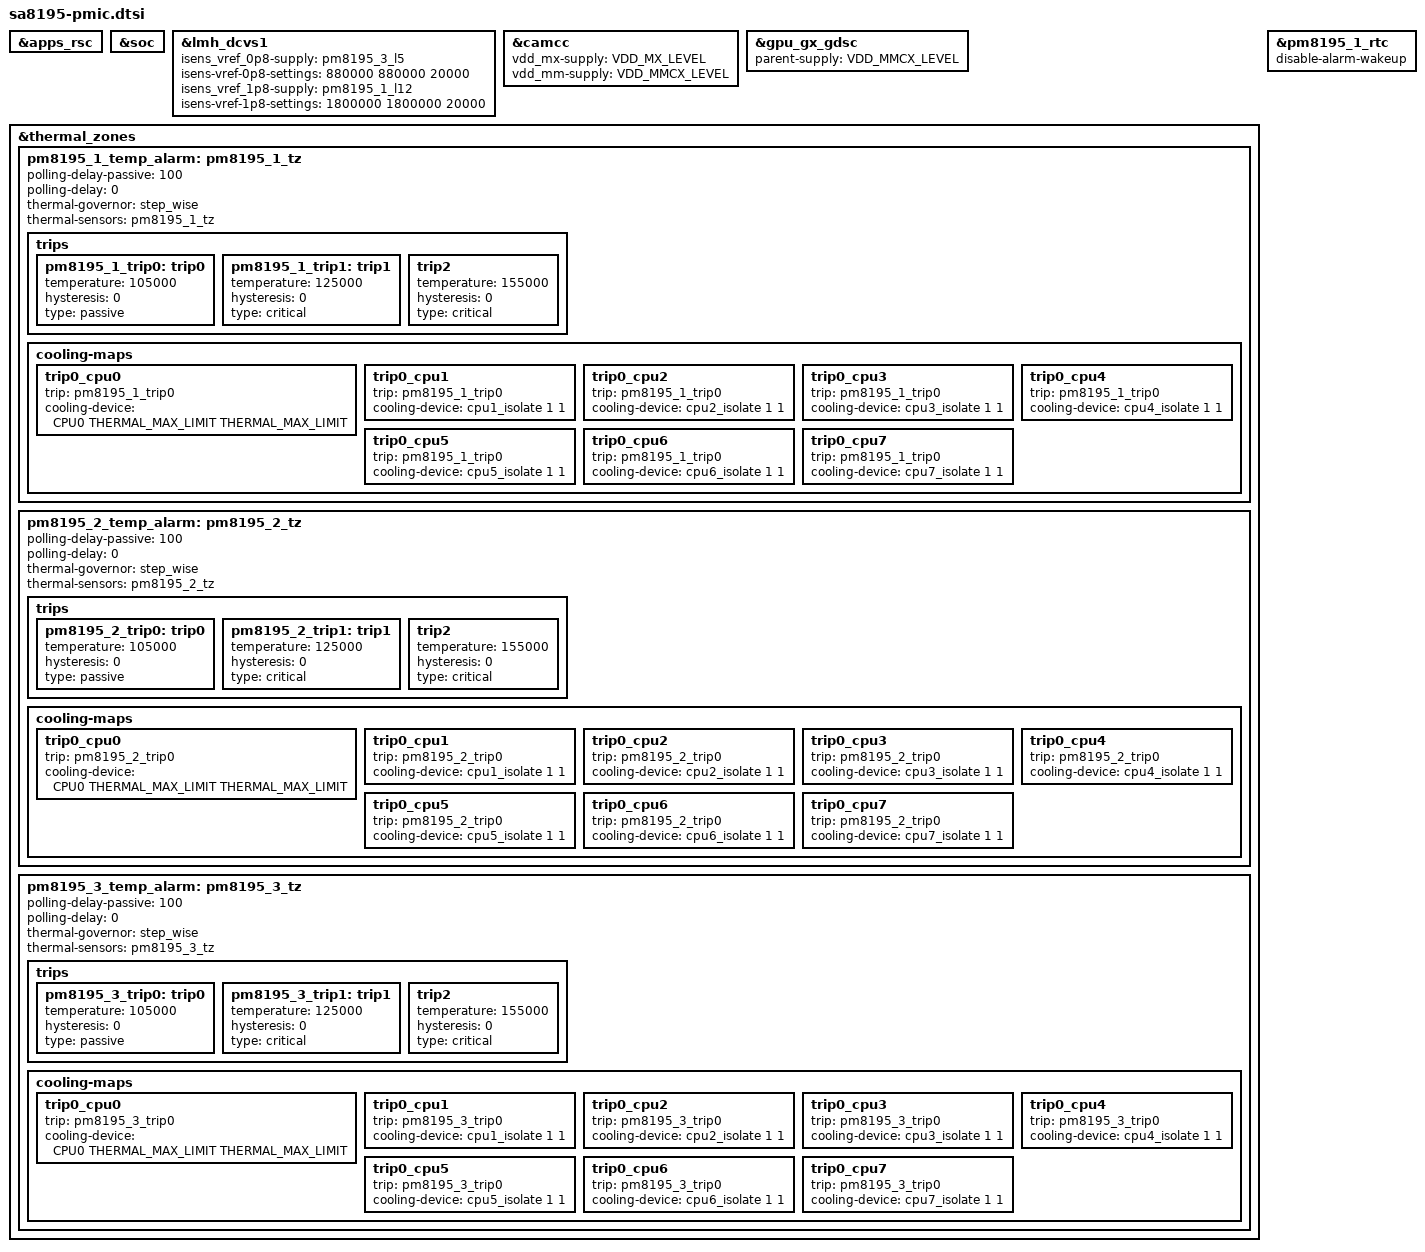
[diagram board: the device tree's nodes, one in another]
/* Remove regulator nodes specific to sdmshrike */
&apps_rsc {
	/* Logical rails */
	/delete-node/ rpmh-regulator-cxlvl;
	/delete-node/ rpmh-regulator-mxlvl;
	/delete-node/ rpmh-regulator-gfxlvl;
	/delete-node/ rpmh-regulator-lmxlvl;
	/delete-node/ rpmh-regulator-lcxlvl;
	/delete-node/ rpmh-regulator-mmcxlvl;
	/delete-node/ rpmh-regulator-msslvl;
	/delete-node/ rpmh-regulator-ebilvl;

	/* PM8150_1 regulators */
	/delete-node/ rpmh-regulator-smpa5;
	/delete-node/ rpmh-regulator-ldoa3;
	/delete-node/ rpmh-regulator-ldoa5;
	/delete-node/ rpmh-regulator-ldoa6;
	/delete-node/ rpmh-regulator-ldoa7;
	/delete-node/ rpmh-regulator-ldoa9;
	/delete-node/ rpmh-regulator-ldoa11;
	/delete-node/ rpmh-regulator-ldoa12;
	/delete-node/ rpmh-regulator-ldoa13;
	/delete-node/ rpmh-regulator-ldoa15;
	/delete-node/ rpmh-regulator-ldoa16;
	/delete-node/ rpmh-regulator-ldoa18;
	/delete-node/ rpmh-regulator-smpe4;
	/delete-node/ rpmh-regulator-smpe5;
	/delete-node/ rpmh-regulator-ldoe1;
	/delete-node/ rpmh-regulator-ldoe2;
	/delete-node/ rpmh-regulator-ldoe5;
	/delete-node/ rpmh-regulator-ldoe7;
	/delete-node/ rpmh-regulator-ldoe10;
	/delete-node/ rpmh-regulator-ldoe13;
	/delete-node/ rpmh-regulator-ldoe14;
	/delete-node/ rpmh-regulator-ldoe15;
	/delete-node/ rpmh-regulator-ldoe16;
	/delete-node/ rpmh-regulator-ldoe17;
	/delete-node/ rpmh-regulator-smpc6;
	/delete-node/ rpmh-regulator-smpc7;
	/delete-node/ rpmh-regulator-smpc8;
	/delete-node/ rpmh-regulator-ldoc1;
	/delete-node/ rpmh-regulator-ldoc2;
	/delete-node/ rpmh-regulator-ldoc3;
	/delete-node/ rpmh-regulator-ldoc4;
	/delete-node/ rpmh-regulator-ldoc6;
	/delete-node/ rpmh-regulator-ldoc7;
	/delete-node/ rpmh-regulator-ldoc8;
	/delete-node/ rpmh-regulator-ldoc9;
	/delete-node/ rpmh-regulator-ldoc10;
	/delete-node/ rpmh-regulator-ldoc11;
	/delete-node/ rpmh-regulator-bobc1;
};

&soc {
	/* Stub regulators */
	/delete-node/ regulator-pm8150_1-s4;

	/* refgen-regulator@88e7000 */
	/delete-node/ refgen;
};

&lmh_dcvs1 {
	isens_vref_0p8-supply = <&pm8195_3_l5>;
	isens-vref-0p8-settings = <880000 880000 20000>;
	isens_vref_1p8-supply = <&pm8195_1_l12>;
	isens-vref-1p8-settings = <1800000 1800000 20000>;
};

&camcc {
	vdd_mx-supply = <&VDD_MX_LEVEL>;
	vdd_mm-supply = <&VDD_MMCX_LEVEL>;
};

&gpu_gx_gdsc {
	parent-supply = <&VDD_MMCX_LEVEL>;
};

#include "sa8195p-regulator.dtsi"
#include "pm8195.dtsi"

&thermal_zones {
	pm8195_1_temp_alarm: pm8195_1_tz {
		polling-delay-passive = <100>;
		polling-delay = <0>;
		thermal-governor = "step_wise";
		thermal-sensors = <&pm8195_1_tz>;

		trips {
			pm8195_1_trip0: trip0 {
				temperature = <105000>;
				hysteresis = <0>;
				type = "passive";
			};

			pm8195_1_trip1: trip1 {
				temperature = <125000>;
				hysteresis = <0>;
				type = "critical";
			};

			trip2 {
				temperature = <155000>;
				hysteresis = <0>;
				type = "critical";
			};
		};

		cooling-maps {
			trip0_cpu0 {
				trip = <&pm8195_1_trip0>;
				cooling-device =
					<&CPU0 THERMAL_MAX_LIMIT
						THERMAL_MAX_LIMIT>;
			};

			trip0_cpu1 {
				trip = <&pm8195_1_trip0>;
				cooling-device = <&cpu1_isolate 1 1>;
			};

			trip0_cpu2 {
				trip = <&pm8195_1_trip0>;
				cooling-device = <&cpu2_isolate 1 1>;
			};

			trip0_cpu3 {
				trip = <&pm8195_1_trip0>;
				cooling-device = <&cpu3_isolate 1 1>;
			};

			trip0_cpu4 {
				trip = <&pm8195_1_trip0>;
				cooling-device = <&cpu4_isolate 1 1>;
			};

			trip0_cpu5 {
				trip = <&pm8195_1_trip0>;
				cooling-device = <&cpu5_isolate 1 1>;
			};

			trip0_cpu6 {
				trip = <&pm8195_1_trip0>;
				cooling-device = <&cpu6_isolate 1 1>;
			};

			trip0_cpu7 {
				trip = <&pm8195_1_trip0>;
				cooling-device = <&cpu7_isolate 1 1>;
			};
		};
	};

	pm8195_2_temp_alarm: pm8195_2_tz {
		polling-delay-passive = <100>;
		polling-delay = <0>;
		thermal-governor = "step_wise";
		thermal-sensors = <&pm8195_2_tz>;

		trips {
			pm8195_2_trip0: trip0 {
				temperature = <105000>;
				hysteresis = <0>;
				type = "passive";
			};

			pm8195_2_trip1: trip1 {
				temperature = <125000>;
				hysteresis = <0>;
				type = "critical";
			};

			trip2 {
				temperature = <155000>;
				hysteresis = <0>;
				type = "critical";
			};
		};

		cooling-maps {
			trip0_cpu0 {
				trip = <&pm8195_2_trip0>;
				cooling-device =
					<&CPU0 THERMAL_MAX_LIMIT
						THERMAL_MAX_LIMIT>;
			};

			trip0_cpu1 {
				trip = <&pm8195_2_trip0>;
				cooling-device = <&cpu1_isolate 1 1>;
			};

			trip0_cpu2 {
				trip = <&pm8195_2_trip0>;
				cooling-device = <&cpu2_isolate 1 1>;
			};

			trip0_cpu3 {
				trip = <&pm8195_2_trip0>;
				cooling-device = <&cpu3_isolate 1 1>;
			};

			trip0_cpu4 {
				trip = <&pm8195_2_trip0>;
				cooling-device = <&cpu4_isolate 1 1>;
			};

			trip0_cpu5 {
				trip = <&pm8195_2_trip0>;
				cooling-device = <&cpu5_isolate 1 1>;
			};

			trip0_cpu6 {
				trip = <&pm8195_2_trip0>;
				cooling-device = <&cpu6_isolate 1 1>;
			};

			trip0_cpu7 {
				trip = <&pm8195_2_trip0>;
				cooling-device = <&cpu7_isolate 1 1>;
			};
		};
	};

	pm8195_3_temp_alarm: pm8195_3_tz {
		polling-delay-passive = <100>;
		polling-delay = <0>;
		thermal-governor = "step_wise";
		thermal-sensors = <&pm8195_3_tz>;

		trips {
			pm8195_3_trip0: trip0 {
				temperature = <105000>;
				hysteresis = <0>;
				type = "passive";
			};

			pm8195_3_trip1: trip1 {
				temperature = <125000>;
				hysteresis = <0>;
				type = "critical";
			};

			trip2 {
				temperature = <155000>;
				hysteresis = <0>;
				type = "critical";
			};
		};

		cooling-maps {
			trip0_cpu0 {
				trip = <&pm8195_3_trip0>;
				cooling-device =
					<&CPU0 THERMAL_MAX_LIMIT
						THERMAL_MAX_LIMIT>;
			};

			trip0_cpu1 {
				trip = <&pm8195_3_trip0>;
				cooling-device = <&cpu1_isolate 1 1>;
			};

			trip0_cpu2 {
				trip = <&pm8195_3_trip0>;
				cooling-device = <&cpu2_isolate 1 1>;
			};

			trip0_cpu3 {
				trip = <&pm8195_3_trip0>;
				cooling-device = <&cpu3_isolate 1 1>;
			};

			trip0_cpu4 {
				trip = <&pm8195_3_trip0>;
				cooling-device = <&cpu4_isolate 1 1>;
			};

			trip0_cpu5 {
				trip = <&pm8195_3_trip0>;
				cooling-device = <&cpu5_isolate 1 1>;
			};

			trip0_cpu6 {
				trip = <&pm8195_3_trip0>;
				cooling-device = <&cpu6_isolate 1 1>;
			};

			trip0_cpu7 {
				trip = <&pm8195_3_trip0>;
				cooling-device = <&cpu7_isolate 1 1>;
			};
		};
	};
};

&pm8195_1_rtc {
	disable-alarm-wakeup;
};
